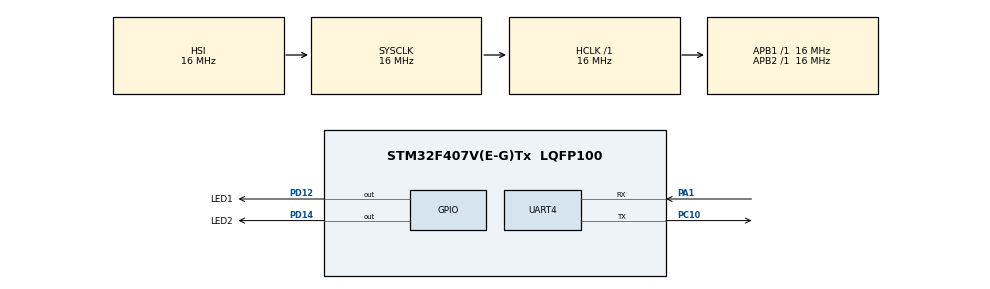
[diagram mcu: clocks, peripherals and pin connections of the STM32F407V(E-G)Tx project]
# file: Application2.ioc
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Mcu.Family=STM32F4
PD12.GPIO_Label=LED1
RCC.CortexFreq_Value=16000000
PC10.Signal=UART4_TX
PC10.Mode=Asynchronous
UART4.VirtualMode=Asynchronous
ProjectManager.StackSize=0x400
ProjectManager.TargetToolchain=STM32CubeIDE
RCC.LSE_VALUE=32768
PA1.Signal=UART4_RX
RCC.AHBFreq_Value=16000000
RCC.HSE_VALUE=25000000
board=custom
RCC.VCOOutputFreq_Value=192000000
RCC.APB2Freq_Value=16000000
PA1.Mode=Asynchronous
PD14.GPIO_Label=LED2
Mcu.Name=STM32F407V(E-G)Tx
PD14.Signal=GPIO_Output
RCC.SYSCLKFreq_VALUE=16000000
Mcu.Package=LQFP100
PD12.Signal=GPIO_Output
ProjectManager.HeapSize=0x200
RCC.HSI_VALUE=16000000
NVIC.PriorityGroup=NVIC_PRIORITYGROUP_4
RCC.APB1Freq_Value=16000000

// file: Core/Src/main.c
/* USER CODE BEGIN Header */
/**
  ******************************************************************************
  * @file           : main.c
  * @brief          : Main program body
  ******************************************************************************
  * @attention
  *
  * <h2><center>&copy; Copyright (c) 2022 STMicroelectronics.
  * All rights reserved.</center></h2>
  *
  * This software component is licensed by ST under BSD 3-Clause license,
  * the "License"; You may not use this file except in compliance with the
  * License. You may obtain a copy of the License at:
  *                        opensource.org/licenses/BSD-3-Clause
  *
  ******************************************************************************
  */
/* USER CODE END Header */
#include "main.h"
#include "usart.h"
#include "gpio.h"

/* USER CODE BEGIN Includes */
#include "string.h"
/* USER CODE END Includes */

void SystemClock_Config(void);

int main(void)
{

  /* MCU Configuration--------------------------------------------------------*/

  /* Reset of all peripherals, Initializes the Flash interface and the Systick. */
  HAL_Init();

  /* Configure the system clock */
  SystemClock_Config();

  /* Initialize all configured peripherals */
  MX_GPIO_Init();
  MX_UART4_Init();

  /* Infinite loop */
  while (1)
  {

    /* USER CODE BEGIN 3 */
	HAL_UART_Transmit(&huart4, (uint8_t*)"This is ver 6\r\n", strlen( (char*)"This is ver 6\r\n"), 500);
	HAL_GPIO_TogglePin(LED1_GPIO_Port, LED1_Pin|LED2_Pin);
	HAL_Delay(500);
  }
  /* USER CODE END 3 */
}

void SystemClock_Config(void)
{
  RCC_OscInitTypeDef RCC_OscInitStruct = {0};
  RCC_ClkInitTypeDef RCC_ClkInitStruct = {0};

  /** Configure the main internal regulator output voltage
  */
  __HAL_RCC_PWR_CLK_ENABLE();
  __HAL_PWR_VOLTAGESCALING_CONFIG(PWR_REGULATOR_VOLTAGE_SCALE1);
  /** Initializes the RCC Oscillators according to the specified parameters
  * in the RCC_OscInitTypeDef structure.
  */
  RCC_OscInitStruct.OscillatorType = RCC_OSCILLATORTYPE_HSI;
  RCC_OscInitStruct.HSIState = RCC_HSI_ON;
  RCC_OscInitStruct.HSICalibrationValue = RCC_HSICALIBRATION_DEFAULT;
  RCC_OscInitStruct.PLL.PLLState = RCC_PLL_NONE;
  if (HAL_RCC_OscConfig(&RCC_OscInitStruct) != HAL_OK)
  {
    Error_Handler();
  }
  /** Initializes the CPU, AHB and APB buses clocks
  */
  RCC_ClkInitStruct.ClockType = RCC_CLOCKTYPE_HCLK|RCC_CLOCKTYPE_SYSCLK
                              |RCC_CLOCKTYPE_PCLK1|RCC_CLOCKTYPE_PCLK2;
  RCC_ClkInitStruct.SYSCLKSource = RCC_SYSCLKSOURCE_HSI;
  RCC_ClkInitStruct.AHBCLKDivider = RCC_SYSCLK_DIV1;
  RCC_ClkInitStruct.APB1CLKDivider = RCC_HCLK_DIV1;
  RCC_ClkInitStruct.APB2CLKDivider = RCC_HCLK_DIV1;

  if (HAL_RCC_ClockConfig(&RCC_ClkInitStruct, FLASH_LATENCY_0) != HAL_OK)
  {
    Error_Handler();
  }
}

void Error_Handler(void)
{
  __disable_irq();
  while (1)
  {
  }
}

/************************ (C) COPYRIGHT STMicroelectronics *****END OF FILE****/
